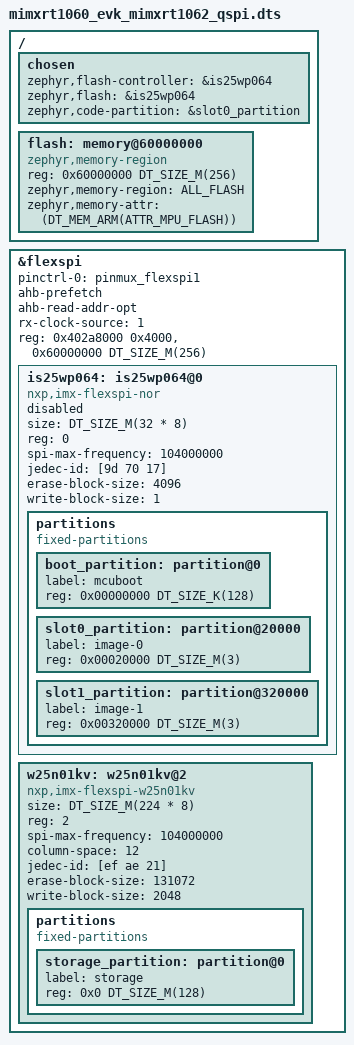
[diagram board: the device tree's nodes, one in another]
/*
 * Copyright 2024 NXP
 *
 * SPDX-License-Identifier: Apache-2.0
 */

#include "mimxrt1060_evk.dtsi"
#include <zephyr/dt-bindings/memory-attr/memory-attr-arm.h>

/ {
	chosen {
		zephyr,flash-controller = &is25wp064;
		zephyr,flash = &is25wp064;
		zephyr,code-partition = &slot0_partition;
	};

	flash: memory@60000000 {
		compatible = "zephyr,memory-region", "mmio-sram";
		reg = <0x60000000 DT_SIZE_M(256)>;
		zephyr,memory-region = "ALL_FLASH";
		zephyr,memory-attr = <(DT_MEM_ARM(ATTR_MPU_FLASH))>;
	};
};

&flexspi {
	status = "okay";
	pinctrl-0 = <&pinmux_flexspi1>;
	pinctrl-names = "default";
	ahb-prefetch;
	ahb-read-addr-opt;
	rx-clock-source = <1>;
	reg = <0x402a8000 0x4000>, <0x60000000 DT_SIZE_M(256)>;
	is25wp064: is25wp064@0 {
		compatible = "nxp,imx-flexspi-nor";
		size = <DT_SIZE_M(32 * 8)>;
		reg = <0>;
		spi-max-frequency = <104000000>;
		status = "disabled";
		jedec-id = [9d 70 17];
		erase-block-size = <4096>;
		write-block-size = <1>;

		partitions {
			compatible = "fixed-partitions";
			#address-cells = <1>;
			#size-cells = <1>;

			/*
			 * Partition sizes must be aligned
			 * to the flash memory sector size of 4KB.
			 */
			boot_partition: partition@0 {
				label = "mcuboot";
				reg = <0x00000000 DT_SIZE_K(128)>;
			};
			slot0_partition: partition@20000 {
				label = "image-0";
				reg = <0x00020000 DT_SIZE_M(3)>;
			};
			slot1_partition: partition@320000 {
				label = "image-1";
				reg = <0x00320000 DT_SIZE_M(3)>;
			};
//			storage_partition: partition@620000 {
//				label = "storage";
//				reg = <0x00620000 (DT_SIZE_M(2) - DT_SIZE_K(128))>;
//			};
		};
	};
	w25n01kv: w25n01kv@2 {
		compatible = "nxp,imx-flexspi-w25n01kv";
		size = <DT_SIZE_M(224 * 8)>;
		reg = <2>;
		spi-max-frequency = <104000000>;
		column-space = <12>;
		status = "okay";
		jedec-id = [ef ae 21];
		erase-block-size = <131072>;
		write-block-size = <2048>;

		partitions {
			compatible = "fixed-partitions";
			#address-cells = <1>;
			#size-cells = <1>;
			storage_partition: partition@0 {
				label = "storage";
				reg = <0x0 DT_SIZE_M(128)>;
			};
		};
	};
};
